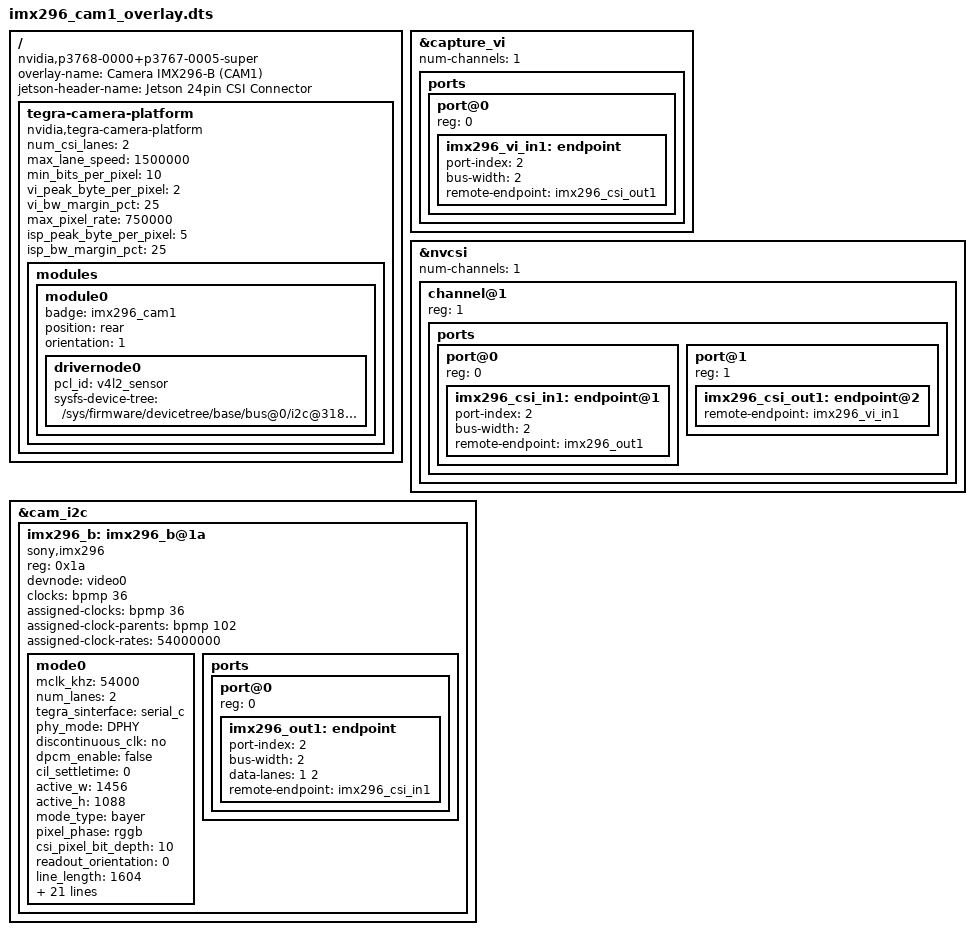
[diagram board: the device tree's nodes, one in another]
// SPDX-License-Identifier: GPL-2.0
/*
 * Device Tree Overlay — Sony IMX296 on CAM1 (Jetson Orin Nano Super, P3768)
 *
 * Hardware assumptions:
 *   - Camera on CAM1 CSI connector
 *   - port-index <2> = serial_c (CAM1 on P3768)
 *   - I2C address 0x1a on cam_i2c (i2c@3180000) — shared with CAM0
 *   - 2-lane MIPI CSI-2 DPHY
 *   - 54 MHz MCLK (delivered as 51 MHz by bpmp)
 */

/dts-v1/;
/plugin/;

/ {
	overlay-name = "Camera IMX296-B (CAM1)";
	jetson-header-name = "Jetson 24pin CSI Connector";
	compatible = "nvidia,p3768-0000+p3767-0005-super",
	             "nvidia,p3768-0000+p3767-0005",
	             "nvidia,p3768-0000+p3767-0004-super",
	             "nvidia,p3768-0000+p3767-0004",
	             "nvidia,p3768-0000+p3767-0003-super",
	             "nvidia,p3768-0000+p3767-0003",
	             "nvidia,p3768-0000+p3767-0001-super",
	             "nvidia,p3768-0000+p3767-0001",
	             "nvidia,p3768-0000+p3767-0000-super",
	             "nvidia,p3768-0000+p3767-0000";

	fragment@0 {
		target = <&capture_vi>;

		__overlay__ {
			num-channels = <1>;

			ports {
				#address-cells = <1>;
				#size-cells = <0>;

				port@0 {
					reg = <0>;
					imx296_vi_in1: endpoint {
						port-index = <2>;
						bus-width = <2>;
						remote-endpoint = <&imx296_csi_out1>;
					};
				};
			};
		};
	};

	fragment@1 {
		target = <&nvcsi>;

		__overlay__ {
			num-channels = <1>;
			#address-cells = <1>;
			#size-cells = <0>;

			channel@1 {
				reg = <1>;

				ports {
					#address-cells = <1>;
					#size-cells = <0>;

					port@0 {
						reg = <0>;
						imx296_csi_in1: endpoint@1 {
							port-index = <2>;
							bus-width = <2>;
							remote-endpoint = <&imx296_out1>;
						};
					};

					port@1 {
						reg = <1>;
						imx296_csi_out1: endpoint@2 {
							remote-endpoint = <&imx296_vi_in1>;
						};
					};
				};
			};
		};
	};

	fragment@2 {
		target = <&cam_i2c>;

		__overlay__ {
			#address-cells = <1>;
			#size-cells = <0>;

			imx296_b: imx296_b@1a {
				compatible = "sony,imx296";
				reg = <0x1a>;
				devnode = "video0";

				clocks = <&bpmp 36>;
				clock-names = "extclk";
				assigned-clocks = <&bpmp 36>;
				assigned-clock-parents = <&bpmp 102>;
				assigned-clock-rates = <54000000>;

				mode0 {
					mclk_khz = "54000";
					num_lanes = "2";
					tegra_sinterface = "serial_c";
					phy_mode = "DPHY";
					discontinuous_clk = "no";
					dpcm_enable = "false";
					cil_settletime = "0";

					active_w = "1456";
					active_h = "1088";
					mode_type = "bayer";
					pixel_phase = "rggb";
					csi_pixel_bit_depth = "10";
					readout_orientation = "0";
					line_length = "1604";
					inherent_gain = "1";
					mclk_multiplier = "16";
					pix_clk_hz = "118800000";

					gain_factor = "16";
					framerate_factor = "1000000";
					exposure_factor = "1000000";
					min_gain_val = "16";
					max_gain_val = "3840";
					step_gain_val = "1";
					default_gain = "16";
					min_hdr_ratio = "1";
					max_hdr_ratio = "1";
					min_framerate = "1000000";
					max_framerate = "60000000";
					step_framerate = "1";
					default_framerate = "60000000";
					min_exp_time = "34";
					max_exp_time = "18220";
					step_exp_time = "1";
					default_exp_time = "16667";
					embedded_metadata_height = "0";
				};

				ports {
					#address-cells = <1>;
					#size-cells = <0>;

					port@0 {
						reg = <0>;
						imx296_out1: endpoint {
							port-index = <2>;
							bus-width = <2>;
							data-lanes = <1 2>;
							remote-endpoint = <&imx296_csi_in1>;
						};
					};
				};
			};
		};
	};

	fragment@3 {
		target-path = "/";

		__overlay__ {
			tegra-camera-platform {
				compatible = "nvidia,tegra-camera-platform";
				num_csi_lanes = <2>;
				max_lane_speed = <1500000>;
				min_bits_per_pixel = <10>;
				vi_peak_byte_per_pixel = <2>;
				vi_bw_margin_pct = <25>;
				max_pixel_rate = <750000>;
				isp_peak_byte_per_pixel = <5>;
				isp_bw_margin_pct = <25>;

				modules {
					module0 {
						badge = "imx296_cam1";
						position = "rear";
						orientation = "1";

						drivernode0 {
							pcl_id = "v4l2_sensor";
							sysfs-device-tree = "/sys/firmware/devicetree/base/bus@0/i2c@3180000/imx296_b@1a";
						};
					};
				};
			};
		};
	};
};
